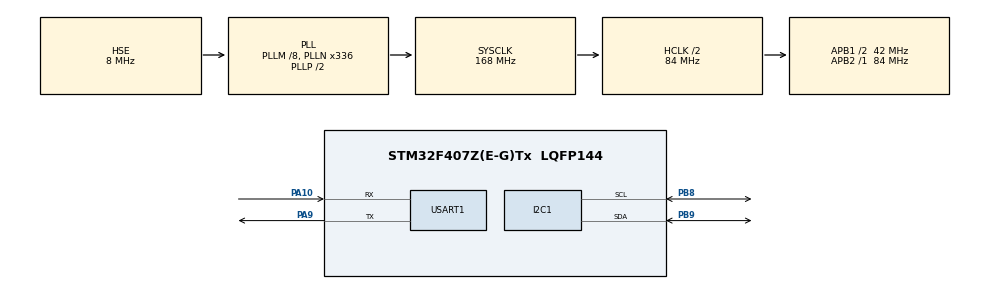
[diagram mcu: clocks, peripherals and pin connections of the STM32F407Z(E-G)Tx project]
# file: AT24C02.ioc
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Mcu.Family=STM32F4
Mcu.Name=STM32F407Z(E-G)Tx
Mcu.Package=LQFP144
NVIC.PriorityGroup=NVIC_PRIORITYGROUP_4
PA10.Mode=Asynchronous
PA10.Signal=USART1_RX
PA9.Mode=Asynchronous
PA9.Signal=USART1_TX
PB8.Mode=I2C
PB8.Signal=I2C1_SCL
PB9.Mode=I2C
PB9.Signal=I2C1_SDA
PH0-OSC_IN.Mode=HSE-External-Oscillator
PH0-OSC_IN.Signal=RCC_OSC_IN
PH1-OSC_OUT.Mode=HSE-External-Oscillator
PH1-OSC_OUT.Signal=RCC_OSC_OUT
ProjectManager.HeapSize=0x200
ProjectManager.StackSize=0x400
ProjectManager.TargetToolchain=MDK-ARM V5.27
RCC.48MHZClocksFreq_Value=84000000
RCC.AHBCLKDivider=RCC_SYSCLK_DIV2
RCC.AHBFreq_Value=84000000
RCC.APB1CLKDivider=RCC_HCLK_DIV2
RCC.APB1Freq_Value=42000000
RCC.APB1TimFreq_Value=84000000
RCC.APB2Freq_Value=84000000
RCC.APB2TimFreq_Value=84000000
RCC.CortexFreq_Value=84000000
RCC.HCLKFreq_Value=84000000
RCC.HSE_VALUE=8000000
RCC.HSI_VALUE=16000000
RCC.LSE_VALUE=32768
RCC.PLLM=8
RCC.PLLN=336
RCC.PLLSourceVirtual=RCC_PLLSOURCE_HSE
RCC.SYSCLKFreq_VALUE=168000000
RCC.SYSCLKSource=RCC_SYSCLKSOURCE_PLLCLK
RCC.VCOOutputFreq_Value=336000000
USART1.VirtualMode=VM_ASYNC
board=custom

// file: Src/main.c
/* USER CODE BEGIN Header */
/**
  ******************************************************************************
  * @file           : main.c
  * @brief          : Main program body
  ******************************************************************************
  * @attention
  *
  * <h2><center>&copy; Copyright (c) 2020 STMicroelectronics.
  * All rights reserved.</center></h2>
  *
  * This software component is licensed by ST under BSD 3-Clause license,
  * the "License"; You may not use this file except in compliance with the
  * License. You may obtain a copy of the License at:
  *                        opensource.org/licenses/BSD-3-Clause
  *
  ******************************************************************************
  */
/* USER CODE END Header */

#include "main.h"
#include "i2c.h"
#include "usart.h"
#include "gpio.h"
#include <string.h>

#define ADDR_24LCxx_Write 0xA0
#define ADDR_24LCxx_Read 0xA1
#define BufferSize 256
uint8_t WriteBuffer[BufferSize],ReadBuffer[BufferSize];
uint16_t i;

void SystemClock_Config(void);

int main(void)
{

  /* MCU Configuration--------------------------------------------------------*/

  /* Reset of all peripherals, Initializes the Flash interface and the Systick. */
  HAL_Init();

  /* Configure the system clock */
  SystemClock_Config();

  /* Initialize all configured peripherals */
  MX_GPIO_Init();
  MX_I2C1_Init();
  MX_USART1_UART_Init();
  /* USER CODE BEGIN 2 */
	for(i=0; i<256; i++)
    WriteBuffer[i]=i;    /* WriteBuffer init */

//	printf("\r\n***************I2C Example 测试*******************************\r\n");	//AT24C02一次必须写入八个字节
//	for (int j=0; j<32; j++)
//  {															//写地址          内部地址  八位数据					写入数组指针 写入字节数
//		if(HAL_I2C_Mem_Write(&hi2c1, ADDR_24LCxx_Write, 8*j, I2C_MEMADD_SIZE_8BIT,WriteBuffer+8*j,8, 1000) == HAL_OK)
//		{
//			printf("\r\n EEPROM 24C02 Write Test OK \r\n");
//			HAL_Delay(20);
//		}
//		else
//		{
//			HAL_Delay(20);
//			printf("\r\n EEPROM 24C02 Write Test False \r\n");
//		}
//	}

	// wrinte date to EEPROM   如果要一次写一个字节，写256次，用这里的代码
	for(i=0;i<BufferSize;i++)
	{
		HAL_I2C_Mem_Write(&hi2c1, ADDR_24LCxx_Write, i, I2C_MEMADD_SIZE_8BIT,&WriteBuffer[i],1,0xff);//使用I2C块读，出错。因此采用此种方式，逐个单字节写入
		HAL_Delay(5);//此处延时必加，与AT24C02写时序有关
	}
	printf("\r\n EEPROM 24C02 Write Test OK \r\n");

	HAL_I2C_Mem_Read(&hi2c1, ADDR_24LCxx_Read, 0, I2C_MEMADD_SIZE_8BIT,ReadBuffer,BufferSize, 0xff);

	for(i=0; i<256; i++)
		printf("0x%02X  ",ReadBuffer[i]);

	if(memcmp(ReadBuffer,WriteBuffer,256) == 0)
		printf("OK");
	else
		printf("ERROR");
  /* USER CODE END 2 */

  /* Infinite loop */
  while (1)
  {

  }
}

void SystemClock_Config(void)
{
  RCC_OscInitTypeDef RCC_OscInitStruct = {0};
  RCC_ClkInitTypeDef RCC_ClkInitStruct = {0};

  /** Configure the main internal regulator output voltage
  */
  __HAL_RCC_PWR_CLK_ENABLE();
  __HAL_PWR_VOLTAGESCALING_CONFIG(PWR_REGULATOR_VOLTAGE_SCALE1);
  /** Initializes the CPU, AHB and APB busses clocks
  */
  RCC_OscInitStruct.OscillatorType = RCC_OSCILLATORTYPE_HSE;
  RCC_OscInitStruct.HSEState = RCC_HSE_ON;
  RCC_OscInitStruct.PLL.PLLState = RCC_PLL_ON;
  RCC_OscInitStruct.PLL.PLLSource = RCC_PLLSOURCE_HSE;
  RCC_OscInitStruct.PLL.PLLM = 8;
  RCC_OscInitStruct.PLL.PLLN = 336;
  RCC_OscInitStruct.PLL.PLLP = RCC_PLLP_DIV2;
  RCC_OscInitStruct.PLL.PLLQ = 4;
  if (HAL_RCC_OscConfig(&RCC_OscInitStruct) != HAL_OK)
  {
    Error_Handler();
  }
  /** Initializes the CPU, AHB and APB busses clocks
  */
  RCC_ClkInitStruct.ClockType = RCC_CLOCKTYPE_HCLK|RCC_CLOCKTYPE_SYSCLK
                              |RCC_CLOCKTYPE_PCLK1|RCC_CLOCKTYPE_PCLK2;
  RCC_ClkInitStruct.SYSCLKSource = RCC_SYSCLKSOURCE_PLLCLK;
  RCC_ClkInitStruct.AHBCLKDivider = RCC_SYSCLK_DIV2;
  RCC_ClkInitStruct.APB1CLKDivider = RCC_HCLK_DIV2;
  RCC_ClkInitStruct.APB2CLKDivider = RCC_HCLK_DIV1;

  if (HAL_RCC_ClockConfig(&RCC_ClkInitStruct, FLASH_LATENCY_2) != HAL_OK)
  {
    Error_Handler();
  }
}

void Error_Handler(void)
{
}

/************************ (C) COPYRIGHT STMicroelectronics *****END OF FILE****/
